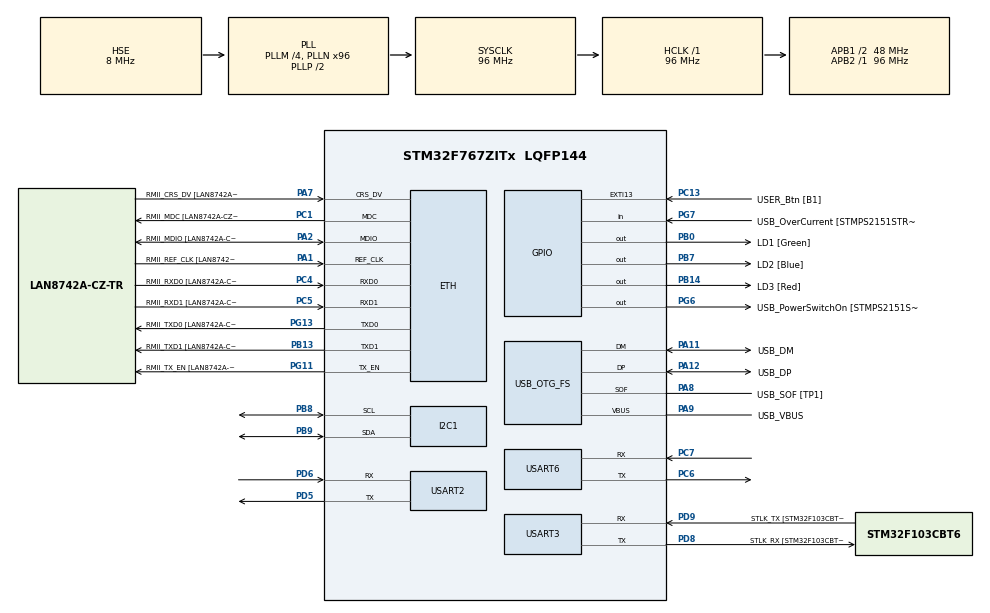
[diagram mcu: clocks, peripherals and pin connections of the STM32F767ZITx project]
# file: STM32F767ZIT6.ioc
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CORTEX_M7.AccessPermission-Cortex_Memory_Protection_Unit_Region0_Settings=MPU_REGION_FULL_ACCESS
CORTEX_M7.AccessPermission-Cortex_Memory_Protection_Unit_Region1_Settings=MPU_REGION_FULL_ACCESS
CORTEX_M7.BaseAddress-Cortex_Memory_Protection_Unit_Region0_Settings=0x2007C000
CORTEX_M7.BaseAddress-Cortex_Memory_Protection_Unit_Region1_Settings=0x2007C000
CORTEX_M7.CPU_DCache=Enabled
CORTEX_M7.CPU_ICache=Enabled
CORTEX_M7.DisableExec-Cortex_Memory_Protection_Unit_Region0_Settings=MPU_INSTRUCTION_ACCESS_ENABLE
CORTEX_M7.DisableExec-Cortex_Memory_Protection_Unit_Region1_Settings=MPU_INSTRUCTION_ACCESS_ENABLE
CORTEX_M7.Enable-Cortex_Memory_Protection_Unit_Region0_Settings=MPU_REGION_ENABLE
CORTEX_M7.Enable-Cortex_Memory_Protection_Unit_Region1_Settings=MPU_REGION_ENABLE
CORTEX_M7.IsBufferable-Cortex_Memory_Protection_Unit_Region1_Settings=MPU_ACCESS_BUFFERABLE
CORTEX_M7.IsShareable-Cortex_Memory_Protection_Unit_Region0_Settings=MPU_ACCESS_SHAREABLE
CORTEX_M7.IsShareable-Cortex_Memory_Protection_Unit_Region1_Settings=MPU_ACCESS_SHAREABLE
CORTEX_M7.MPU_Control=MPU_PRIVILEGED_DEFAULT
CORTEX_M7.PREFETCH_ENABLE=1
CORTEX_M7.Size-Cortex_Memory_Protection_Unit_Region0_Settings=MPU_REGION_SIZE_16KB
CORTEX_M7.Size-Cortex_Memory_Protection_Unit_Region1_Settings=MPU_REGION_SIZE_256B
CORTEX_M7.TypeExtField-Cortex_Memory_Protection_Unit_Region0_Settings=MPU_TEX_LEVEL1
ETH.MediaInterface=HAL_ETH_RMII_MODE
ETH.PHY_Name=LAN8742A_PHY_ADDRESS
ETH.PHY_Value=0
ETH.PhyAddress=0
ETH.RxMode=ETH_RXINTERRUPT_MODE
I2C1.Timing=0x20303E5D
IWDG.Prescaler=IWDG_PRESCALER_256
Mcu.Family=STM32F7
Mcu.Name=STM32F767ZITx
Mcu.Package=LQFP144
NVIC.ETH_IRQn=true\:5\:0\:true\:false\:true\:true\:true\:true
NVIC.EXTI15_10_IRQn=true\:5\:0\:true\:false\:true\:true\:true\:true
NVIC.I2C1_ER_IRQn=true\:5\:0\:true\:false\:true\:true\:true\:true
NVIC.I2C1_EV_IRQn=true\:5\:0\:true\:false\:true\:true\:true\:true
NVIC.PriorityGroup=NVIC_PRIORITYGROUP_4
NVIC.USART2_IRQn=true\:5\:0\:true\:false\:true\:true\:true\:true
NVIC.USART6_IRQn=true\:5\:0\:true\:false\:true\:true\:true\:true
PA1.GPIO_Label=RMII_REF_CLK [LAN8742A-CZ-TR_REFCLK0]
PA1.Mode=RMII
PA1.Signal=ETH_REF_CLK
PA10.GPIO_Label=USB_ID
PA10.Signal=USB_OTG_FS_ID
PA11.GPIO_Label=USB_DM
PA11.Mode=Device_Only
PA11.Signal=USB_OTG_FS_DM
PA12.GPIO_Label=USB_DP
PA12.Mode=Device_Only
PA12.Signal=USB_OTG_FS_DP
PA13.GPIO_Label=TMS
PA13.Mode=Serial_Wire
PA13.Signal=SYS_JTMS-SWDIO
PA14.GPIO_Label=TCK
PA14.Mode=Serial_Wire
PA14.Signal=SYS_JTCK-SWCLK
PA2.GPIO_Label=RMII_MDIO [LAN8742A-CZ-TR_MDIO]
PA2.Mode=RMII
PA2.Signal=ETH_MDIO
PA7.GPIO_Label=RMII_CRS_DV [LAN8742A-CZ-TR_CRS_DV]
PA7.Mode=RMII
PA7.Signal=ETH_CRS_DV
PA8.GPIO_Label=USB_SOF [TP1]
PA8.Mode=Activate_SOF_FS
PA8.Signal=USB_OTG_FS_SOF
PA9.GPIO_Label=USB_VBUS
PA9.Mode=Activate_VBUS
PA9.Signal=USB_OTG_FS_VBUS
PB0.GPIO_Label=LD1 [Green]
PB0.Signal=GPIO_Output
PB13.GPIO_Label=RMII_TXD1 [LAN8742A-CZ-TR_TXD1]
PB13.Mode=RMII
PB13.Signal=ETH_TXD1
PB14.GPIO_Label=LD3 [Red]
PB14.Signal=GPIO_Output
PB3.GPIO_Label=SWO
PB3.Signal=SYS_JTDO-SWO
PB7.GPIO_Label=LD2 [Blue]
PB7.Signal=GPIO_Output
PB8.GPIO_Pu=GPIO_PULLUP
PB8.Mode=I2C
PB8.Signal=I2C1_SCL
PB9.GPIO_Pu=GPIO_PULLUP
PB9.Mode=I2C
PB9.Signal=I2C1_SDA
PC1.GPIO_Label=RMII_MDC [LAN8742A-CZ-TR_MDC]
PC1.Mode=RMII
PC1.Signal=ETH_MDC
PC13.GPIO_Label=USER_Btn [B1]
PC13.Signal=GPXTI13
PC14/OSC32_IN.Mode=LSE-External-Oscillator
PC14/OSC32_IN.Signal=RCC_OSC32_IN
PC15/OSC32_OUT.Mode=LSE-External-Oscillator
PC15/OSC32_OUT.Signal=RCC_OSC32_OUT
PC4.GPIO_Label=RMII_RXD0 [LAN8742A-CZ-TR_RXD0]
PC4.Mode=RMII
PC4.Signal=ETH_RXD0
PC5.GPIO_Label=RMII_RXD1 [LAN8742A-CZ-TR_RXD1]
PC5.Mode=RMII
PC5.Signal=ETH_RXD1
PC6.Mode=Asynchronous
PC6.Signal=USART6_TX
PC7.GPIO_ModeDefaultPP=GPIO_MODE_AF_OD
PC7.GPIO_PuPd=GPIO_PULLUP
PC7.Mode=Asynchronous
PC7.Signal=USART6_RX
PD5.Mode=Asynchronous
PD5.Signal=USART2_TX
PD6.GPIO_ModeDefaultPP=GPIO_MODE_AF_OD
PD6.GPIO_PuPd=GPIO_PULLUP
PD6.Mode=Asynchronous
PD6.Signal=USART2_RX
PD8.GPIO_Label=STLK_RX [STM32F103CBT6_PA3]
PD8.Mode=Asynchronous
PD8.Signal=USART3_TX
PD9.GPIO_Label=STLK_TX [STM32F103CBT6_PA2]
PD9.GPIO_ModeDefaultPP=GPIO_MODE_AF_OD
PD9.GPIO_PuPd=GPIO_PULLUP
PD9.Mode=Asynchronous
PD9.Signal=USART3_RX
PG11.GPIO_Label=RMII_TX_EN [LAN8742A-CZ-TR_TXEN]
PG11.Mode=RMII
PG11.Signal=ETH_TX_EN
PG13.GPIO_Label=RMII_TXD0 [LAN8742A-CZ-TR_TXD0]
PG13.Mode=RMII
PG13.Signal=ETH_TXD0
PG6.GPIO_Label=USB_PowerSwitchOn [STMPS2151STR_EN]
PG6.Signal=GPIO_Output
PG7.GPIO_Label=USB_OverCurrent [STMPS2151STR_FAULT]
PG7.Signal=GPIO_Input
PH0/OSC_IN.GPIO_Label=MCO [STM32F103CBT6_PA8]
PH0/OSC_IN.Mode=HSE-External-Clock-Source
PH0/OSC_IN.Signal=RCC_OSC_IN
PH1/OSC_OUT.Mode=HSE-External-Clock-Source
PH1/OSC_OUT.Signal=RCC_OSC_OUT
ProjectManager.HeapSize=0x200
ProjectManager.StackSize=0x400
ProjectManager.TargetToolchain=STM32CubeIDE
RCC.48MHZClocksFreq_Value=24000000
RCC.AHBFreq_Value=96000000
RCC.APB1CLKDivider=RCC_HCLK_DIV2
RCC.APB1Freq_Value=48000000
RCC.APB1TimFreq_Value=96000000
RCC.APB2Freq_Value=96000000
RCC.APB2TimFreq_Value=96000000
RCC.CortexFreq_Value=96000000
RCC.HCLKFreq_Value=96000000
RCC.HSE_VALUE=8000000
RCC.HSI_VALUE=16000000
RCC.PLLM=4
RCC.PLLMUL=RCC_PLL_MUL9
RCC.PLLN=96
RCC.PLLQ=4
RCC.PRESCALERUSB=RCC_USBCLKSOURCE_PLL_DIV1_5
RCC.RTCClockSelection=RCC_RTCCLKSOURCE_LSE
RCC.SYSCLKFreq_VALUE=96000000
RCC.SYSCLKSource=RCC_SYSCLKSOURCE_PLLCLK
RCC.SYSCLKSourceVirtual=RCC_SYSCLKSOURCE_PLLCLK
RCC.USBFreq_Value=48000000
RCC.VCOOutputFreq_Value=192000000
RTC.Format=RTC_FORMAT_BIN
USART2.OverrunDisableParam=ADVFEATURE_OVERRUN_DISABLE
USART2.VirtualMode-Asynchronous=VM_ASYNC
USART3.OverrunDisableParam=ADVFEATURE_OVERRUN_DISABLE
USART3.VirtualMode-Asynchronous=VM_ASYNC
USART6.OverrunDisableParam=ADVFEATURE_OVERRUN_DISABLE
USART6.VirtualMode-Asynchronous=VM_ASYNC
USB_OTG_FS.VirtualMode=Device_Only
VP_CRC_VS_CRC.Mode=CRC_Activate
VP_IWDG_VS_IWDG.Mode=IWDG_Activate
VP_RNG_VS_RNG.Mode=RNG_Activate
VP_RTC_VS_RTC_Activate.Mode=RTC_Enabled
VP_RTC_VS_RTC_Calendar.Mode=RTC_Calendar
VP_RTC_VS_RTC_WakeUp_intern.Mode=WakeUp
board=NUCLEO-F767ZI

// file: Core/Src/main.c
/* USER CODE BEGIN Header */
/**
  ******************************************************************************
  * @file           : main.c
  * @brief          : Main program body
  ******************************************************************************
  * @attention
  *
  * Copyright (c) 2023 STMicroelectronics.
  * All rights reserved.
  *
  * This software is licensed under terms that can be found in the LICENSE file
  * in the root directory of this software component.
  * If no LICENSE file comes with this software, it is provided AS-IS.
  *
  ******************************************************************************
  */
/* USER CODE END Header */
#include "main.h"
#include "crc.h"
#include "eth.h"
#include "i2c.h"
#include "iwdg.h"
#include "rng.h"
#include "rtc.h"
#include "usart.h"
#include "usb_otg.h"
#include "gpio.h"

void SystemClock_Config(void);
static void MPU_Initialize(void);
static void MPU_Config(void);

/* USER CODE BEGIN 0 */
int hal_hwinit(void)
{
	  /* Initialize all configured peripherals */
	  MX_GPIO_Init();
	  // MX_ETH_Init();
	  MX_USART3_UART_Init();
	  // MX_USB_OTG_FS_PCD_Init();
	  MX_CRC_Init();
	  MX_USART2_UART_Init();
	  MX_RNG_Init();
	  MX_USART6_UART_Init();
	  //MX_IWDG_Init();
	  MX_RTC_Init();
	  //MX_I2C1_Init();
	  HAL_PWR_DisableBkUpAccess();
	  return 0;
}
/* USER CODE END 0 */

int main(void)
{

  /* Enable I-Cache---------------------------------------------------------*/
  SCB_EnableICache();

  /* Enable D-Cache---------------------------------------------------------*/
  SCB_EnableDCache();

  /* MCU Configuration--------------------------------------------------------*/

  /* Reset of all peripherals, Initializes the Flash interface and the Systick. */
  HAL_Init();

  /* MPU Configuration--------------------------------------------------------*/
  MPU_Config();

#if 0
  /* Configure the system clock */
  SystemClock_Config();

  /* Initialize all configured peripherals */
  MX_GPIO_Init();
  MX_ETH_Init();
  MX_USART3_UART_Init();
  MX_USB_OTG_FS_PCD_Init();
  MX_CRC_Init();
  MX_USART2_UART_Init();
  MX_RNG_Init();
  MX_USART6_UART_Init();
  MX_IWDG_Init();
  MX_RTC_Init();
  MX_I2C1_Init();
  /* USER CODE BEGIN 2 */
#endif
 extern int app_start(void);
  app_start();
  /* USER CODE END 2 */

  /* Infinite loop */
  while (1)
  {

  }
}

void SystemClock_Config(void)
{
  RCC_OscInitTypeDef RCC_OscInitStruct = {0};
  RCC_ClkInitTypeDef RCC_ClkInitStruct = {0};

  /** Configure LSE Drive Capability
  */
  HAL_PWR_EnableBkUpAccess();
  __HAL_RCC_LSEDRIVE_CONFIG(RCC_LSEDRIVE_LOW);

  /** Configure the main internal regulator output voltage
  */
  __HAL_RCC_PWR_CLK_ENABLE();
  __HAL_PWR_VOLTAGESCALING_CONFIG(PWR_REGULATOR_VOLTAGE_SCALE3);

  /** Initializes the RCC Oscillators according to the specified parameters
  * in the RCC_OscInitTypeDef structure.
  */
  RCC_OscInitStruct.OscillatorType = RCC_OSCILLATORTYPE_LSI|RCC_OSCILLATORTYPE_HSE|RCC_OSCILLATORTYPE_LSE;
  RCC_OscInitStruct.HSEState = RCC_HSE_BYPASS;
  RCC_OscInitStruct.LSEState = RCC_LSE_ON;
  RCC_OscInitStruct.LSIState = RCC_LSI_ON;
  RCC_OscInitStruct.PLL.PLLState = RCC_PLL_ON;
  RCC_OscInitStruct.PLL.PLLSource = RCC_PLLSOURCE_HSE;
  RCC_OscInitStruct.PLL.PLLM = 4;
  RCC_OscInitStruct.PLL.PLLN = 96;
  RCC_OscInitStruct.PLL.PLLP = RCC_PLLP_DIV2;
  RCC_OscInitStruct.PLL.PLLQ = 4;
  RCC_OscInitStruct.PLL.PLLR = 2;
  if (HAL_RCC_OscConfig(&RCC_OscInitStruct) != HAL_OK)
  {
    Error_Handler();
  }

  /** Activate the Over-Drive mode
  */
  if (HAL_PWREx_EnableOverDrive() != HAL_OK)
  {
    Error_Handler();
  }

  /** Initializes the CPU, AHB and APB buses clocks
  */
  RCC_ClkInitStruct.ClockType = RCC_CLOCKTYPE_HCLK|RCC_CLOCKTYPE_SYSCLK
                              |RCC_CLOCKTYPE_PCLK1|RCC_CLOCKTYPE_PCLK2;
  RCC_ClkInitStruct.SYSCLKSource = RCC_SYSCLKSOURCE_PLLCLK;
  RCC_ClkInitStruct.AHBCLKDivider = RCC_SYSCLK_DIV1;
  RCC_ClkInitStruct.APB1CLKDivider = RCC_HCLK_DIV2;
  RCC_ClkInitStruct.APB2CLKDivider = RCC_HCLK_DIV1;

  if (HAL_RCC_ClockConfig(&RCC_ClkInitStruct, FLASH_LATENCY_3) != HAL_OK)
  {
    Error_Handler();
  }
}

/* USER CODE BEGIN 4 */
#define LARGE_BUFFER_AREA 1
/* USER CODE END 4 */

/* MPU Configuration */

void MPU_Config(void)
{
  MPU_Region_InitTypeDef MPU_InitStruct = {0};

  /* Disables the MPU */
  HAL_MPU_Disable();

  /** Initializes and configures the Region and the memory to be protected
  */
  MPU_InitStruct.Enable = MPU_REGION_ENABLE;
  MPU_InitStruct.Number = MPU_REGION_NUMBER0;
#if defined(LARGE_BUFFER_AREA)
  MPU_InitStruct.BaseAddress = 0x20070000;
  MPU_InitStruct.Size = MPU_REGION_SIZE_64KB;
  //MPU_InitStruct.BaseAddress = 0x20078000;
  //MPU_InitStruct.Size = MPU_REGION_SIZE_32KB;
#else
  MPU_InitStruct.BaseAddress = 0x2007C000;
  MPU_InitStruct.Size = MPU_REGION_SIZE_16KB;
#endif
  MPU_InitStruct.SubRegionDisable = 0x0;
  MPU_InitStruct.TypeExtField = MPU_TEX_LEVEL1;
  MPU_InitStruct.AccessPermission = MPU_REGION_FULL_ACCESS;
  MPU_InitStruct.DisableExec = MPU_INSTRUCTION_ACCESS_ENABLE;
  MPU_InitStruct.IsShareable = MPU_ACCESS_SHAREABLE;
  MPU_InitStruct.IsCacheable = MPU_ACCESS_NOT_CACHEABLE;
  MPU_InitStruct.IsBufferable = MPU_ACCESS_NOT_BUFFERABLE;

  HAL_MPU_ConfigRegion(&MPU_InitStruct);

  /** Initializes and configures the Region and the memory to be protected
  */
  MPU_InitStruct.Number = MPU_REGION_NUMBER1;
#if defined(LARGE_BUFFER_AREA)
  MPU_InitStruct.Size = MPU_REGION_SIZE_2KB;
  //MPU_InitStruct.Size = MPU_REGION_SIZE_1KB;
#else
  MPU_InitStruct.Size = MPU_REGION_SIZE_256B;
#endif
  MPU_InitStruct.TypeExtField = MPU_TEX_LEVEL0;
  MPU_InitStruct.IsBufferable = MPU_ACCESS_BUFFERABLE;

  HAL_MPU_ConfigRegion(&MPU_InitStruct);
  /* Enables the MPU */
  HAL_MPU_Enable(MPU_PRIVILEGED_DEFAULT);

}

void Error_Handler(void)
{
  __disable_irq();
  while (1)
  {
  }
}
